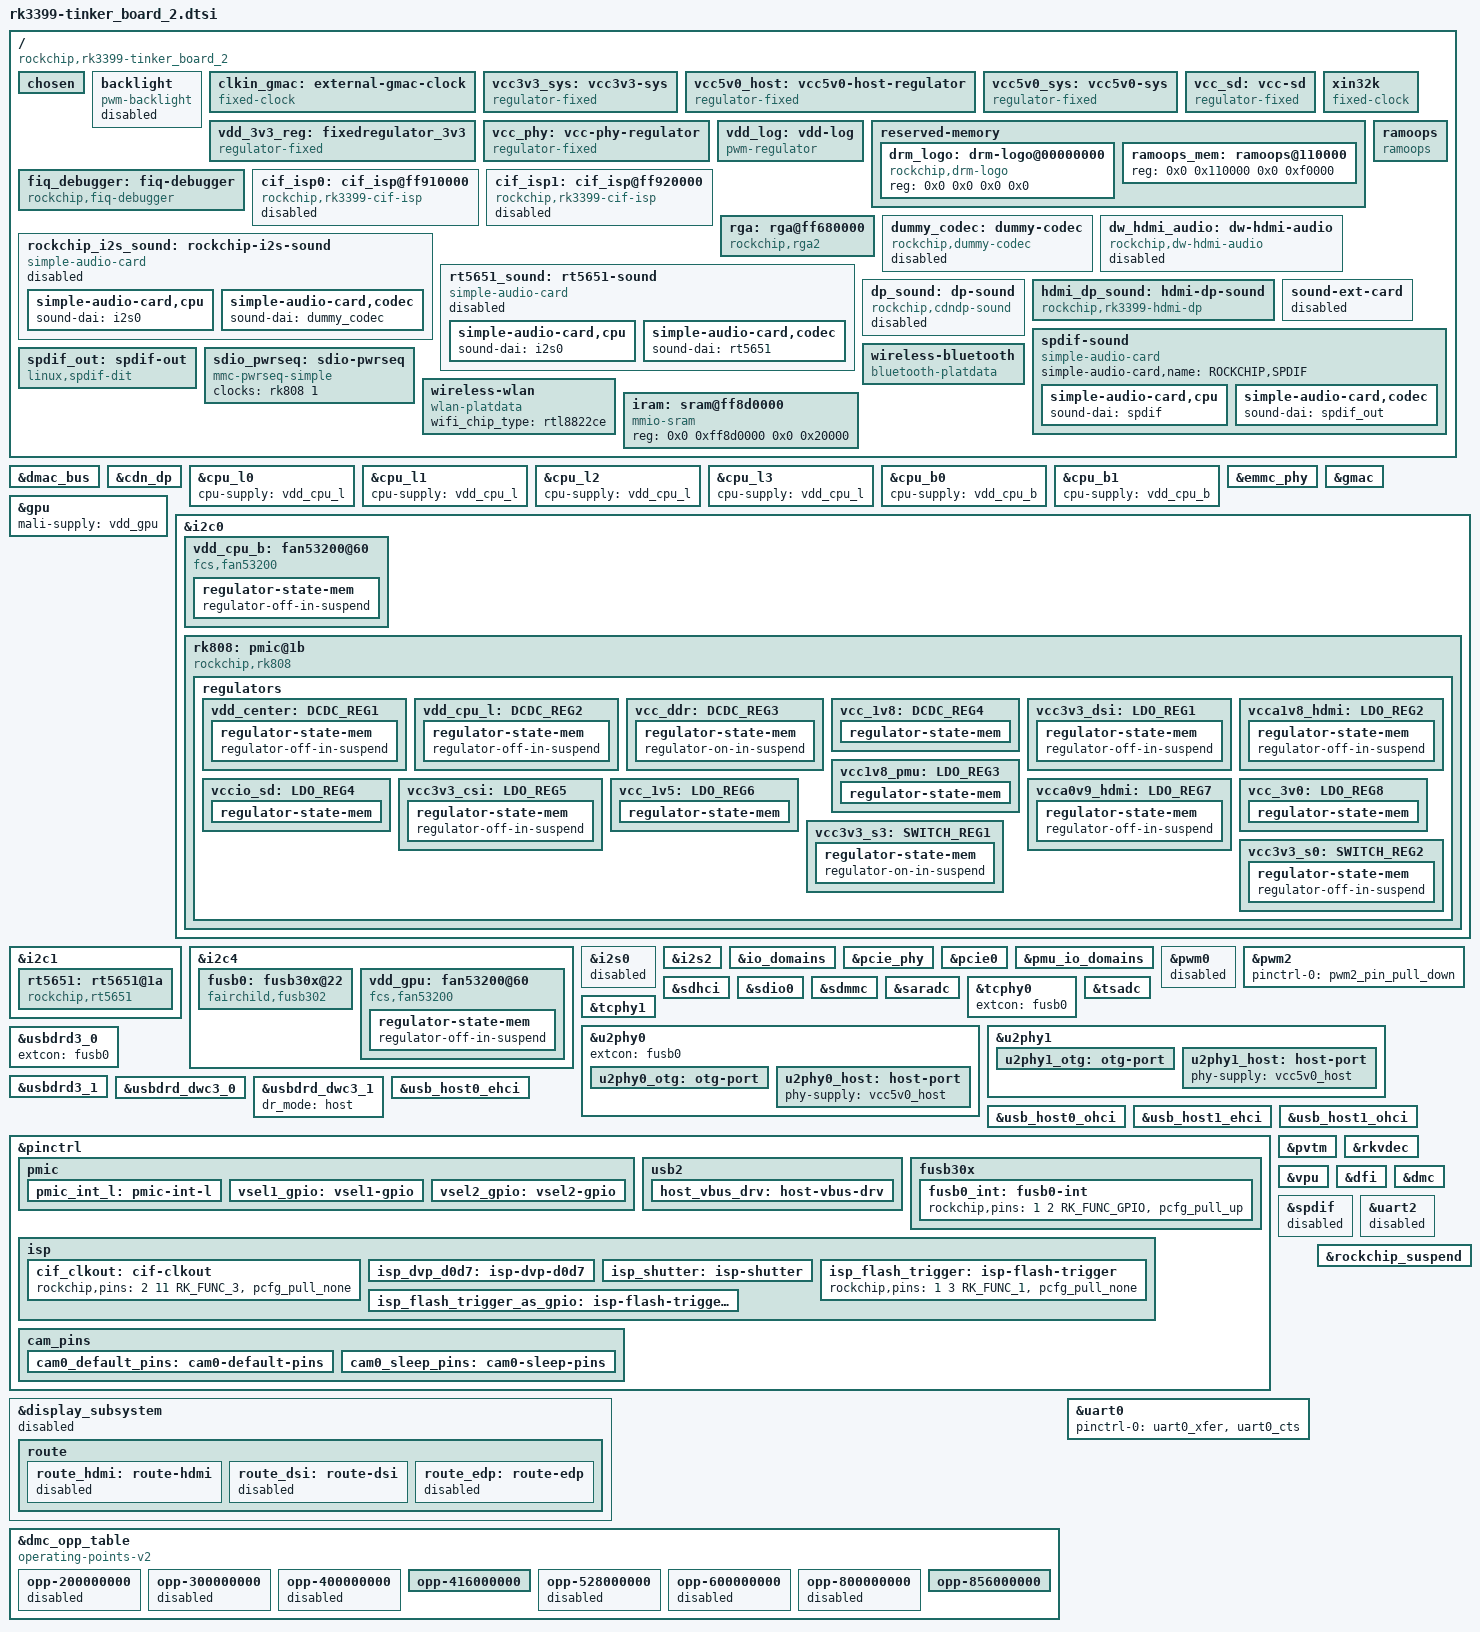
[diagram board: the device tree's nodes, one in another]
/*
 * Copyright (c) 2016 Fuzhou Rockchip Electronics Co., Ltd
 *
 * This file is dual-licensed: you can use it either under the terms
 * of the GPL or the X11 license, at your option. Note that this dual
 * licensing only applies to this file, and not this project as a
 * whole.
 *
 *  a) This file is free software; you can redistribute it and/or
 *     modify it under the terms of the GNU General Public License as
 *     published by the Free Software Foundation; either version 2 of the
 *     License, or (at your option) any later version.
 *
 *     This file is distributed in the hope that it will be useful,
 *     but WITHOUT ANY WARRANTY; without even the implied warranty of
 *     MERCHANTABILITY or FITNESS FOR A PARTICULAR PURPOSE.  See the
 *     GNU General Public License for more details.
 *
 * Or, alternatively,
 *
 *  b) Permission is hereby granted, free of charge, to any person
 *     obtaining a copy of this software and associated documentation
 *     files (the "Software"), to deal in the Software without
 *     restriction, including without limitation the rights to use,
 *     copy, modify, merge, publish, distribute, sublicense, and/or
 *     sell copies of the Software, and to permit persons to whom the
 *     Software is furnished to do so, subject to the following
 *     conditions:
 *
 *     The above copyright notice and this permission notice shall be
 *     included in all copies or substantial portions of the Software.
 *
 *     THE SOFTWARE IS PROVIDED "AS IS", WITHOUT WARRANTY OF ANY KIND,
 *     EXPRESS OR IMPLIED, INCLUDING BUT NOT LIMITED TO THE WARRANTIES
 *     OF MERCHANTABILITY, FITNESS FOR A PARTICULAR PURPOSE AND
 *     NONINFRINGEMENT. IN NO EVENT SHALL THE AUTHORS OR COPYRIGHT
 *     HOLDERS BE LIABLE FOR ANY CLAIM, DAMAGES OR OTHER LIABILITY,
 *     WHETHER IN AN ACTION OF CONTRACT, TORT OR OTHERWISE, ARISING
 *     FROM, OUT OF OR IN CONNECTION WITH THE SOFTWARE OR THE USE OR
 *     OTHER DEALINGS IN THE SOFTWARE.
 */

#include <dt-bindings/display/drm_mipi_dsi.h>
#include "dt-bindings/pwm/pwm.h"
#include <dt-bindings/soc/rockchip-io-domain.h>
#include "rk3399.dtsi"
#include "rk3399-opp.dtsi"
#include "rk3399-vop-clk-set.dtsi"

/ {
	compatible = "rockchip,rk3399-tinker_board_2", "rockchip,rk3399";

	chosen {
		bootargs = "earlycon=uart8250,mmio32,0xff1a0000 swiotlb=1 console=ttyFIQ0 rw rootfstype=ext4 rootwait coherent_pool=1m";
	};

	backlight: backlight {
		status = "disabled";
		compatible = "pwm-backlight";
		//pwms = <&pwm0 0 25000 0>;
		brightness-levels = <
			  0   1   2   3   4   5   6   7
			  8   9  10  11  12  13  14  15
			 16  17  18  19  20  21  22  23
			 24  25  26  27  28  29  30  31
			 32  33  34  35  36  37  38  39
			 40  41  42  43  44  45  46  47
			 48  49  50  51  52  53  54  55
			 56  57  58  59  60  61  62  63
			 64  65  66  67  68  69  70  71
			 72  73  74  75  76  77  78  79
			 80  81  82  83  84  85  86  87
			 88  89  90  91  92  93  94  95
			 96  97  98  99 100 101 102 103
			104 105 106 107 108 109 110 111
			112 113 114 115 116 117 118 119
			120 121 122 123 124 125 126 127
			128 129 130 131 132 133 134 135
			136 137 138 139 140 141 142 143
			144 145 146 147 148 149 150 151
			152 153 154 155 156 157 158 159
			160 161 162 163 164 165 166 167
			168 169 170 171 172 173 174 175
			176 177 178 179 180 181 182 183
			184 185 186 187 188 189 190 191
			192 193 194 195 196 197 198 199
			200 201 202 203 204 205 206 207
			208 209 210 211 212 213 214 215
			216 217 218 219 220 221 222 223
			224 225 226 227 228 229 230 231
			232 233 234 235 236 237 238 239
			240 241 242 243 244 245 246 247
			248 249 250 251 252 253 254 255>;
		default-brightness-level = <200>;
	};

	clkin_gmac: external-gmac-clock {
		compatible = "fixed-clock";
		clock-frequency = <125000000>;
		clock-output-names = "clkin_gmac";
		#clock-cells = <0>;
	};

	vcc3v3_sys: vcc3v3-sys {
		compatible = "regulator-fixed";
		regulator-name = "vcc3v3_sys";
		regulator-always-on;
		regulator-boot-on;
		regulator-min-microvolt = <3300000>;
		regulator-max-microvolt = <3300000>;
	};

	vcc5v0_host: vcc5v0-host-regulator {
		compatible = "regulator-fixed";
		enable-active-high;
		gpio = <&gpio4 25 GPIO_ACTIVE_HIGH>;
		pinctrl-names = "default";
		pinctrl-0 = <&host_vbus_drv>;
		regulator-name = "vcc5v0_host";
		regulator-always-on;
	};

	vcc5v0_sys: vcc5v0-sys {
		compatible = "regulator-fixed";
		regulator-name = "vcc5v0_sys";
		regulator-always-on;
		regulator-boot-on;
		regulator-min-microvolt = <5000000>;
		regulator-max-microvolt = <5000000>;
	};

	vcc_sd: vcc-sd {
		compatible = "regulator-fixed";
		enable-active-high;
		pinctrl-names = "default";
		regulator-name = "vcc_sd";
		regulator-min-microvolt = <3300000>;
		regulator-max-microvolt = <3300000>;
	};

	vdd_3v3_reg: fixedregulator_3v3 {
		compatible = "regulator-fixed";
		regulator-name = "3v3";
		regulator-min-microvolt = <3300000>;
		regulator-max-microvolt = <3300000>;
		regulator-always-on;
	};

	vcc_phy: vcc-phy-regulator {
		compatible = "regulator-fixed";
		regulator-name = "vcc_phy";
		regulator-always-on;
		regulator-boot-on;
	};

	vdd_log: vdd-log {
		compatible = "pwm-regulator";
		pwms = <&pwm2 0 25000 1>;
		regulator-name = "vdd_log";
		regulator-min-microvolt = <800000>;
		regulator-max-microvolt = <1400000>;
		regulator-always-on;
		regulator-boot-on;

		/* for rockchip boot on */
		rockchip,pwm_id= <2>;
		rockchip,pwm_voltage = <900000>;
	};

	xin32k: xin32k {
		compatible = "fixed-clock";
		clock-frequency = <32768>;
		clock-output-names = "xin32k";
		#clock-cells = <0>;
	};

	reserved-memory {
		#address-cells = <2>;
		#size-cells = <2>;
		ranges;

		drm_logo: drm-logo@00000000 {
			compatible = "rockchip,drm-logo";
			reg = <0x0 0x0 0x0 0x0>;
		};

		ramoops_mem: ramoops@110000 {
			reg = <0x0 0x110000 0x0 0xf0000>;
			reg-names = "ramoops_mem";
		};
	};

	ramoops: ramoops {
		compatible = "ramoops";
		record-size = <0x0 0x40000>;
		console-size = <0x0 0x80000>;
		ftrace-size = <0x0 0x00000>;
		pmsg-size = <0x0 0x00000>;
		memory-region = <&ramoops_mem>;
	};

	fiq_debugger: fiq-debugger {
		compatible = "rockchip,fiq-debugger";
		rockchip,serial-id = <2>;
		rockchip,signal-irq = <182>;
		rockchip,wake-irq = <0>;
		rockchip,irq-mode-enable = <1>;  /* If enable uart uses irq instead of fiq */
		rockchip,baudrate = <1500000>;  /* Only 115200 and 1500000 */
		pinctrl-names = "default";
		pinctrl-0 = <&uart2c_xfer>;
		status = "okay";
	};

	cif_isp0: cif_isp@ff910000 {
		compatible = "rockchip,rk3399-cif-isp";
		rockchip,grf = <&grf>;
		reg = <0x0 0xff910000 0x0 0x4000>, <0x0 0xff968000 0x0 0x8000>;
		reg-names = "register", "dsihost-register";
		clocks =
			<&cru ACLK_ISP0_NOC>, <&cru ACLK_ISP0_WRAPPER>,
			<&cru HCLK_ISP0_NOC>, <&cru HCLK_ISP0_WRAPPER>,
			<&cru SCLK_ISP0>, <&cru SCLK_DPHY_RX0_CFG>,
			<&cru SCLK_CIF_OUT>, <&cru SCLK_CIF_OUT>,
			<&cru SCLK_MIPIDPHY_REF>;
		clock-names =
			"aclk_isp0_noc", "aclk_isp0_wrapper",
			"hclk_isp0_noc", "hclk_isp0_wrapper",
			"clk_isp0", "pclk_dphyrx",
			"clk_cif_out", "clk_cif_pll",
			"pclk_dphy_ref";
		interrupts = <GIC_SPI 43 IRQ_TYPE_LEVEL_HIGH 0>;
		interrupt-names = "cif_isp10_irq";
		power-domains = <&power RK3399_PD_ISP0>;
		rockchip,isp,iommu-enable = <1>;
		iommus = <&isp0_mmu>;
		status = "disabled";
	};

	cif_isp1: cif_isp@ff920000 {
		compatible = "rockchip,rk3399-cif-isp";
		rockchip,grf = <&grf>;
		reg = <0x0 0xff920000 0x0 0x4000>, <0x0 0xff968000 0x0 0x8000>;
		reg-names = "register", "dsihost-register";
		clocks =
			<&cru ACLK_ISP1_NOC>, <&cru ACLK_ISP1_WRAPPER>,
			<&cru HCLK_ISP1_NOC>, <&cru HCLK_ISP1_WRAPPER>,
			<&cru SCLK_ISP1>, <&cru PCLK_ISP1_WRAPPER>,
			<&cru SCLK_DPHY_TX1RX1_CFG>,
			<&cru PCLK_MIPI_DSI1>, <&cru SCLK_MIPIDPHY_CFG>,
			<&cru SCLK_CIF_OUT>, <&cru SCLK_CIF_OUT>,
			<&cru SCLK_MIPIDPHY_REF>;
		clock-names =
			"aclk_isp1_noc", "aclk_isp1_wrapper",
			"hclk_isp1_noc", "hclk_isp1_wrapper",
			"clk_isp1", "pclkin_isp1",
			"pclk_dphytxrx",
			"pclk_mipi_dsi","mipi_dphy_cfg",
			"clk_cif_out", "clk_cif_pll",
			"pclk_dphy_ref";
		interrupts = <GIC_SPI 44 IRQ_TYPE_LEVEL_HIGH 0>;
		interrupt-names = "cif_isp10_irq";
		power-domains = <&power RK3399_PD_ISP1>;
		rockchip,isp,iommu-enable = <1>;
		iommus = <&isp1_mmu>;
		status = "disabled";
	};

	rga: rga@ff680000 {
		compatible = "rockchip,rga2";
		dev_mode = <1>;
		reg = <0x0 0xff680000 0x0 0x1000>;
		interrupts = <GIC_SPI 55 IRQ_TYPE_LEVEL_HIGH 0>;
		clocks = <&cru ACLK_RGA>, <&cru HCLK_RGA>, <&cru SCLK_RGA_CORE>;
		clock-names = "aclk_rga", "hclk_rga", "clk_rga";
		power-domains = <&power RK3399_PD_RGA>;
		status = "okay";
	};

	dummy_codec: dummy-codec {
		status = "disabled";
		compatible = "rockchip,dummy-codec";
		#sound-dai-cells = <0>;
		clocks = <&cru SCLK_I2S_8CH_OUT>;
		clock-names = "mclk";
		pinctrl-names = "default";
		pinctrl-0 = <&i2s_8ch_mclk>;
	};

	rockchip_i2s_sound: rockchip-i2s-sound {
		status = "disabled";
		compatible = "simple-audio-card";
		simple-audio-card,name = "rockchip,rockchip-i2s-sound";
		simple-audio-card,format = "i2s";
		simple-audio-card,mclk-fs = <256>;
		simple-audio-card,cpu {
			sound-dai = <&i2s0>;
		};
		simple-audio-card,codec {
			sound-dai = <&dummy_codec>;
		};
	};

	rt5651_sound: rt5651-sound {
		status = "disabled";
		compatible = "simple-audio-card";
		simple-audio-card,format = "i2s";
		simple-audio-card,name = "realtek,rt5651-codec";
		simple-audio-card,mclk-fs = <256>;
		simple-audio-card,widgets =
			"Microphone", "Mic Jack",
			"Headphone", "Headphone Jack";
		simple-audio-card,routing =
			"Mic Jack", "MICBIAS1",
			"IN1P", "Mic Jack",
			"Headphone Jack", "HPOL",
			"Headphone Jack", "HPOR";
		simple-audio-card,cpu {
			sound-dai = <&i2s0>;
		};
		simple-audio-card,codec {
			sound-dai = <&rt5651>;
		};
	};

	dw_hdmi_audio: dw-hdmi-audio {
		status = "disabled";
		compatible = "rockchip,dw-hdmi-audio";
		#sound-dai-cells = <0>;
	};

	dp_sound: dp-sound {
		status = "disabled";
		compatible = "rockchip,cdndp-sound";
		rockchip,cpu = <&spdif>;
		rockchip,codec = <&cdn_dp 1>;
	};

/*
	hdmi_sound: hdmi-sound {
		status = "okay";
		compatible = "simple-audio-card";
		simple-audio-card,format = "i2s";
		simple-audio-card,mclk-fs = <256>;
		simple-audio-card,name = "rockchip,hdmi";

		simple-audio-card,cpu {
			sound-dai = <&i2s2>;
		};
		simple-audio-card,codec {
			sound-dai = <&hdmi>;
		};
	};
*/

	hdmi_dp_sound: hdmi-dp-sound {
		status = "okay";
		compatible = "rockchip,rk3399-hdmi-dp";
		rockchip,cpu = <&i2s2>;
		rockchip,codec = <&hdmi>, <&cdn_dp>;
	};

	sound-ext-card {
		status = "disabled";
	};

	spdif-sound {
		status = "okay";
		compatible = "simple-audio-card";
		simple-audio-card,name = "ROCKCHIP,SPDIF";
		simple-audio-card,cpu {
			sound-dai = <&spdif>;
		};
		simple-audio-card,codec {
			sound-dai = <&spdif_out>;
		};
	};

	spdif_out: spdif-out {
		status = "okay";
		compatible = "linux,spdif-dit";
		#sound-dai-cells = <0>;
	};

	sdio_pwrseq: sdio-pwrseq {
		compatible = "mmc-pwrseq-simple";
		clocks = <&rk808 1>;
		clock-names = "ext_clock";
		pinctrl-names = "default";
		//pinctrl-0 = <&wifi_enable_h>;

		/*
		 * On the module itself this is one of these (depending
		 * on the actual card populated):
		 * - SDIO_RESET_L_WL_REG_ON
		 * - PDN (power down when low)
		 */
		//reset-gpios = <&gpio0 10 GPIO_ACTIVE_LOW>; /* GPIO0_B2 */
	};

	wireless-wlan {
		compatible = "wlan-platdata";
		wifi_chip_type = "rtl8822ce";
		status = "okay";
	};

	wireless-bluetooth {
		compatible = "bluetooth-platdata";
		clocks = <&rk808 1>;
		clock-names = "ext_clock";
		//wifi-bt-power-toggle;
		//uart_rts_gpios = <&gpio2 19 GPIO_ACTIVE_LOW>; /* GPIO2_C3 */
		//pinctrl-names = "default", "rts_gpio";
		//pinctrl-0 = <&uart0_rts>;
		//pinctrl-1 = <&uart0_gpios>;
		//BT,power_gpio  = <&gpio3 19 GPIO_ACTIVE_HIGH>; /* GPIOx_xx */
		//BT,reset_gpio    = <&gpio0 9 GPIO_ACTIVE_HIGH>; /* GPIO0_B1 */
		BT,wake_gpio     = <&gpio2 26 GPIO_ACTIVE_HIGH>; /* GPIO2_D2 */
		//BT,wake_host_irq = <&gpio0 4 GPIO_ACTIVE_HIGH>; /* GPIO0_A4 */
		status = "okay";
	};

	/* first 64k(0xff8c0000~0xff8d0000) for ddr and suspend */
	iram: sram@ff8d0000 {
		compatible = "mmio-sram";
		reg = <0x0 0xff8d0000 0x0 0x20000>; /* 128k */
	};
};

&dmac_bus {
	iram = <&iram>;
	rockchip,force-iram;
};

&cdn_dp {
	status = "okay";
	extcon = <&fusb0>;
	phys = <&tcphy0_dp>;
};

&cpu_l0 {
	cpu-supply = <&vdd_cpu_l>;
};

&cpu_l1 {
	cpu-supply = <&vdd_cpu_l>;
};

&cpu_l2 {
	cpu-supply = <&vdd_cpu_l>;
};

&cpu_l3 {
	cpu-supply = <&vdd_cpu_l>;
};

&cpu_b0 {
	cpu-supply = <&vdd_cpu_b>;
};

&cpu_b1 {
	cpu-supply = <&vdd_cpu_b>;
};

&emmc_phy {
	status = "okay";
};

&gmac {
	phy-supply = <&vcc_phy>;
	phy-mode = "rgmii";
	clock_in_out = "output";
	snps,reset-gpio = <&gpio3 15 GPIO_ACTIVE_LOW>;
	snps,reset-active-low;
	snps,reset-delays-us = <0 16000 72000>;
	assigned-clocks = <&cru SCLK_RMII_SRC>;
	assigned-clock-parents = <&cru SCLK_MAC>;
	assigned-clock-rates = <125000000>;
	wolirq-gpio = <&gpio3 16 GPIO_ACTIVE_LOW>;
	pinctrl-names = "default";
	pinctrl-0 = <&rgmii_pins>;
	tx_delay = <0x25>;
	rx_delay = <0x20>;
	wakeup-enable = "0";
	status = "okay";
};

&gpu {
	status = "okay";
	mali-supply = <&vdd_gpu>;
};

&i2c0 {
	status = "okay";
	i2c-scl-rising-time-ns = <168>;
	i2c-scl-falling-time-ns = <4>;
	clock-frequency = <400000>;

	vdd_cpu_b: fan53200@60 {
		compatible = "fcs,fan53200";
		reg = <0x60>;
		vin-supply = <&vcc5v0_sys>;
		regulator-compatible = "fan53555-reg";
		pinctrl-names = "default";
		pinctrl-0 = <&vsel1_gpio>;
		vsel-gpios = <&gpio1 17 GPIO_ACTIVE_HIGH>;
		regulator-name = "vdd_cpu_b";
		regulator-min-microvolt = <800000>;
		regulator-max-microvolt = <1250000>;
		regulator-ramp-delay = <1000>;
		fcs,suspend-voltage-selector = <0>;
		regulator-always-on;
		regulator-boot-on;
		regulator-initial-state = <3>;
			regulator-state-mem {
			regulator-off-in-suspend;
		};
	};

	rk808: pmic@1b {
		compatible = "rockchip,rk808";
		reg = <0x1b>;
		interrupt-parent = <&gpio1>;
		interrupts = <18 IRQ_TYPE_LEVEL_LOW>;
		pinctrl-names = "default";
		pinctrl-0 = <&pmic_int_l>;
		rockchip,system-power-controller;
		wakeup-source;
		#clock-cells = <1>;
		clock-output-names = "rk808-clkout1", "rk808-clkout2";

		vcc1-supply = <&vcc3v3_sys>;
		vcc2-supply = <&vcc3v3_sys>;
		vcc3-supply = <&vcc3v3_sys>;
		vcc4-supply = <&vcc3v3_sys>;
		vcc6-supply = <&vcc3v3_sys>;
		vcc7-supply = <&vcc3v3_sys>;
		vcc8-supply = <&vcc3v3_sys>;
		vcc9-supply = <&vcc3v3_sys>;
		vcc10-supply = <&vcc3v3_sys>;
		vcc11-supply = <&vcc3v3_sys>;
		vcc12-supply = <&vcc3v3_sys>;
		vddio-supply = <&vcc_3v0>;

		regulators {
			vdd_center: DCDC_REG1 {
				regulator-always-on;
				regulator-boot-on;
				regulator-min-microvolt = <750000>;
				regulator-max-microvolt = <1350000>;
				regulator-ramp-delay = <6001>;
				regulator-name = "vdd_center";
				regulator-state-mem {
					regulator-off-in-suspend;
				};
			};

			vdd_cpu_l: DCDC_REG2 {
				regulator-always-on;
				regulator-boot-on;
				regulator-min-microvolt = <750000>;
				regulator-max-microvolt = <1350000>;
				regulator-ramp-delay = <6001>;
				regulator-name = "vdd_cpu_l";
				regulator-state-mem {
					regulator-off-in-suspend;
				};
			};

			vcc_ddr: DCDC_REG3 {
				regulator-always-on;
				regulator-boot-on;
				regulator-name = "vcc_ddr";
				regulator-state-mem {
					regulator-on-in-suspend;
				};
			};

			vcc_1v8: DCDC_REG4 {
				regulator-always-on;
				regulator-boot-on;
				regulator-min-microvolt = <1800000>;
				regulator-max-microvolt = <1800000>;
				regulator-name = "vcc_1v8";
				regulator-state-mem {
					regulator-on-in-suspend;
					regulator-suspend-microvolt = <1800000>;
				};
			};

			vcc3v3_dsi: LDO_REG1 {
				regulator-always-on;
				regulator-boot-on;
				regulator-min-microvolt = <3300000>;
				regulator-max-microvolt = <3300000>;
				regulator-name = "vcc3v3_dsi";
				regulator-state-mem {
					regulator-off-in-suspend;
				};
			};

			vcca1v8_hdmi: LDO_REG2 {
				regulator-always-on;
				regulator-boot-on;
				regulator-min-microvolt = <1800000>;
				regulator-max-microvolt = <1800000>;
				regulator-name = "vcca1v8_hdmi";
				regulator-state-mem {
					regulator-off-in-suspend;
				};
			};

			vcc1v8_pmu: LDO_REG3 {
				regulator-always-on;
				regulator-boot-on;
				regulator-min-microvolt = <1800000>;
				regulator-max-microvolt = <1800000>;
				regulator-name = "vcc1v8_pmu";
				regulator-state-mem {
					regulator-on-in-suspend;
					regulator-suspend-microvolt = <1800000>;
				};
			};

			vccio_sd: LDO_REG4 {
				regulator-always-on;
				regulator-boot-on;
				regulator-min-microvolt = <1800000>;
				regulator-max-microvolt = <3000000>;
				regulator-name = "vccio_sd";
				regulator-state-mem {
					regulator-on-in-suspend;
					regulator-suspend-microvolt = <3000000>;
				};
			};

			vcc3v3_csi: LDO_REG5 {
				regulator-always-on;
				regulator-boot-on;
				regulator-min-microvolt = <3300000>;
				regulator-max-microvolt = <3300000>;
				regulator-name = "vcc3v3_csi";
				regulator-state-mem {
					regulator-off-in-suspend;
				};
			};

			vcc_1v5: LDO_REG6 {
				regulator-always-on;
				regulator-boot-on;
				regulator-min-microvolt = <1500000>;
				regulator-max-microvolt = <1500000>;
				regulator-name = "vcc_1v5";
				regulator-state-mem {
					regulator-on-in-suspend;
					regulator-suspend-microvolt = <1500000>;
				};
			};

			vcca0v9_hdmi: LDO_REG7 {
				regulator-always-on;
				regulator-boot-on;
				regulator-min-microvolt = <900000>;
				regulator-max-microvolt = <900000>;
				regulator-name = "vcca0v9_hdmi";
				regulator-state-mem {
					regulator-off-in-suspend;
				};
			};

			vcc_3v0: LDO_REG8 {
				regulator-always-on;
				regulator-boot-on;
				regulator-min-microvolt = <3000000>;
				regulator-max-microvolt = <3000000>;
				regulator-name = "vcc_3v0";
				regulator-state-mem {
					regulator-on-in-suspend;
					regulator-suspend-microvolt = <3000000>;
				};
			};

			vcc3v3_s3: SWITCH_REG1 {
				regulator-always-on;
				regulator-boot-on;
				regulator-name = "vcc3v3_s3";
				regulator-state-mem {
					regulator-on-in-suspend;
				};
			};

			vcc3v3_s0: SWITCH_REG2 {
				regulator-always-on;
				regulator-boot-on;
				regulator-name = "vcc3v3_s0";
				regulator-state-mem {
					regulator-off-in-suspend;
				};
			};
		};
	};
};

&i2c1 {
	status = "okay";
	i2c-scl-rising-time-ns = <300>;
	i2c-scl-falling-time-ns = <15>;

	rt5651: rt5651@1a {
		#sound-dai-cells = <0>;
		compatible = "rockchip,rt5651";
		reg = <0x1a>;
		clocks = <&cru SCLK_I2S_8CH_OUT>;
		clock-names = "mclk";
		pinctrl-names = "default";
		pinctrl-0 = <&i2s_8ch_mclk>;
		spk-con-gpio = <&gpio0 11 GPIO_ACTIVE_HIGH>;
		hp-det-gpio = <&gpio4 28 GPIO_ACTIVE_LOW>;
	};
};

&i2c4 {
	status = "okay";
	i2c-scl-rising-time-ns = <475>;
	i2c-scl-falling-time-ns = <26>;

	fusb0: fusb30x@22 {
		compatible = "fairchild,fusb302";
		reg = <0x22>;
		pinctrl-names = "default";
		pinctrl-0 = <&fusb0_int>;
		int-n-gpios = <&gpio1 2 GPIO_ACTIVE_HIGH>;
		//vbus-5v-gpios = <&gpio2 0 GPIO_ACTIVE_HIGH>;
		status = "okay";
	};

	vdd_gpu: fan53200@60 {
		compatible = "fcs,fan53200";
		reg = <0x60>;
		vin-supply = <&vcc5v0_sys>;
		regulator-compatible = "fan53555-reg";
		pinctrl-names = "default";
		pinctrl-0 = <&vsel2_gpio>;
		vsel-gpios = <&gpio1 14 GPIO_ACTIVE_HIGH>;
		regulator-name = "vdd_gpu";
		regulator-min-microvolt = <800000>;
		regulator-max-microvolt = <1200000>;
		regulator-ramp-delay = <1000>;
		fcs,suspend-voltage-selector = <0>;
		regulator-always-on;
		regulator-boot-on;
		regulator-initial-state = <3>;
			regulator-state-mem {
			regulator-off-in-suspend;
		};
	};
};

&i2s0 {
	status = "disable";
	rockchip,i2s-broken-burst-len;
	rockchip,playback-channels = <8>;
	rockchip,capture-channels = <8>;
	#sound-dai-cells = <0>;
};

&i2s2 {
	#sound-dai-cells = <0>;
	status = "okay";
};

&io_domains {
	status = "okay";

	/*
	 * If the uboot use rkdevelop branch, the io-domain is not set
	 * during uboot phase, it will cause the io voltage is not suit for
	 * the hardware,maybe will damage the io of rk3399, so we add
	 * uboot-set value to make sure the value is same with the kernel,
	 * ofcause you must make sure firstly the value here is suit for your
	 * hardware. The available value is defined in
	 * include/dt-bindings/soc/rockchip-io-domain.h, they are
	 * also list here for more convenient configuration:
	 * bt656-supply: RK3399_BT656_VDD_1V8 or RK3399_BT656_VDD_3V3
	 * audio-supply: RK3399_AUDIO_VDD_1V8 or RK3399_AUDIO_VDD_3V3
	 * gpio1830-supply: RK3399_GPIO1833_VDD_1V8 or RK3399_GPIO1833_VDD_3V3
	 * sdmmc-supply: don't need to configure because the voltage
	 *                       is set in source code during runtime.
	 * NOTE:
	 * 1. The value in uboot-set must be enclosed in "()", otherwise will
	 *     cause compile error.
	 * 2. The uboot-set configuration must be cooperated with submit
	 *     in u-boot.
	 */
	uboot-set = <(RK3399_BT656_VDD_3V3 | RK3399_AUDIO_VDD_1V8 |
				RK3399_GPIO1833_VDD_3V3)>;
	bt656-supply = <&vcc_3v0>;		/* bt656_gpio2ab_ms */
	audio-supply = <&vcc_3v0>;		/* audio_gpio3d4a_ms */
	sdmmc-supply = <&vccio_sd>;		/* sdmmc_gpio4b_ms */
	gpio1830-supply = <&vcc_3v0>;		/* gpio1833_gpio4cd_ms */
};

&pcie_phy {
	status = "okay";
};

&pcie0 {
	ep-gpios = <&gpio0 12 GPIO_ACTIVE_HIGH>;
	num-lanes = <4>;
	pinctrl-names = "default";
	pinctrl-0 = <&pcie_clkreqn>;
	status = "okay";
};

&pmu_io_domains {
	status = "okay";
	/*
	 * If the uboot use rkdevelop branch, the pmu_io_domain is not set
	 * during uboot phase, it will cause the io voltage is not suit for
	 * the hardware,maybe will damage the io of rk3399, so we add
	 * uboot-set value to make sure the value is same with the kernel,
	 * ofcause you must make sure firstly the value here is suit for your
	 * hardware. The available value is defined in
	 * include/dt-bindings/soc/rockchip-io-domain.h, they are
	 * also list here for more convenient configuration:
	 * pmu1830-supply: RK3399_PMU1830_VDD_1V8 or RK3399_PMU1830_VDD_3V0
	 */
	uboot-set = <RK3399_PMU1830_VDD_3V0>;
	pmu1830-supply = <&vcc_3v0>;
};

&pwm0 {
	status = "disable";
};

&pwm2 {
	status = "okay";
	pinctrl-names = "active";
	pinctrl-0 = <&pwm2_pin_pull_down>;
};

&sdhci {
	bus-width = <8>;
	mmc-hs400-1_8v;
	supports-emmc;
	non-removable;
	keep-power-in-suspend;
	mmc-hs400-enhanced-strobe;
	status = "okay";
};

&sdio0 {
	clock-frequency = <50000000>;
	clock-freq-min-max = <200000 50000000>;
	supports-sdio;
	bus-width = <4>;
	disable-wp;
	cap-sd-highspeed;
	cap-sdio-irq;
	keep-power-in-suspend;
	mmc-pwrseq = <&sdio_pwrseq>;
	non-removable;
	num-slots = <1>;
	pinctrl-names = "default";
	sd-uhs-sdr104;
	status = "okay";
};

&sdmmc {
	clock-frequency = <150000000>;
	clock-freq-min-max = <100000 150000000>;
	supports-sd;
	bus-width = <4>;
	cap-mmc-highspeed;
	cap-sd-highspeed;
	disable-wp;
	num-slots = <1>;
	//sd-uhs-sdr104;
	vmmc-supply = <&vcc_sd>;
	vqmmc-supply = <&vccio_sd>;
	pinctrl-names = "default";
	pinctrl-0 = <&sdmmc_clk &sdmmc_cmd &sdmmc_cd &sdmmc_bus4>;
	status = "okay";
};

&saradc {
	status = "okay";
};

&tcphy0 {
	extcon = <&fusb0>;
	status = "okay";
};

&tcphy1 {
	status = "okay";
};

&tsadc {
	/* tshut mode 0:CRU 1:GPIO */
	rockchip,hw-tshut-mode = <1>;
	/* tshut polarity 0:LOW 1:HIGH */
	rockchip,hw-tshut-polarity = <1>;
	status = "okay";
};

&u2phy0 {
	status = "okay";
	extcon = <&fusb0>;

	u2phy0_otg: otg-port {
		status = "okay";
	};

	u2phy0_host: host-port {
		phy-supply = <&vcc5v0_host>;
		status = "okay";
	};
};

&u2phy1 {
	status = "okay";

	u2phy1_otg: otg-port {
		status = "okay";
	};

	u2phy1_host: host-port {
		phy-supply = <&vcc5v0_host>;
		status = "okay";
	};
};

&usbdrd3_0 {
	status = "okay";
	extcon = <&fusb0>;
};

&usbdrd3_1 {
	status = "okay";
};

&usbdrd_dwc3_0 {
	status = "okay";
};

&usbdrd_dwc3_1 {
	status = "okay";
	dr_mode = "host";
};

&usb_host0_ehci {
	status = "okay";
};

&usb_host0_ohci {
	status = "okay";
};

&usb_host1_ehci {
	status = "okay";
};

&usb_host1_ohci {
	status = "okay";
};

&pinctrl {
	pmic {
		pmic_int_l: pmic-int-l {
			rockchip,pins =
				<1 18 RK_FUNC_GPIO &pcfg_pull_up>,
				<0 9 RK_FUNC_GPIO &pcfg_pull_none>; /* GPIO0_B1 */
		};
		vsel1_gpio: vsel1-gpio {
			rockchip,pins =
				<1 17 RK_FUNC_GPIO &pcfg_pull_down>;
		};
		vsel2_gpio: vsel2-gpio {
			rockchip,pins =
				<1 14 RK_FUNC_GPIO &pcfg_pull_down>;
		};
	};

	usb2 {
		host_vbus_drv: host-vbus-drv {
			rockchip,pins =
				<4 25 RK_FUNC_GPIO &pcfg_pull_none>;
		};
	};

	fusb30x {
		fusb0_int: fusb0-int {
			rockchip,pins = <1 2 RK_FUNC_GPIO &pcfg_pull_up>;
		};
	};

	isp {
		cif_clkout: cif-clkout {
			rockchip,pins =
				/* cif_clkout */
				<2 11 RK_FUNC_3 &pcfg_pull_none>;
		};

		isp_dvp_d0d7: isp-dvp-d0d7 {
			rockchip,pins =
				<4 27 RK_FUNC_GPIO &pcfg_pull_none>,
				/* cif_clkout */
				<2 11 RK_FUNC_3 &pcfg_pull_none>,
				/* cif_data0 */
				<2 2 RK_FUNC_3 &pcfg_pull_none>,
				/* cif_data3 */
				<2 3 RK_FUNC_3 &pcfg_pull_none>,
				/* cif_data4 */
				<2 4 RK_FUNC_3 &pcfg_pull_none>,
				/* cif_data5 */
				<2 5 RK_FUNC_3 &pcfg_pull_none>,
				/* cif_data6 */
				<2 6 RK_FUNC_3 &pcfg_pull_none>,
				/* cif_data7 */
				<2 7 RK_FUNC_3 &pcfg_pull_none>,
				/* cif_sync */
				<2 8 RK_FUNC_3 &pcfg_pull_none>,
				/* cif_href */
				<2 9 RK_FUNC_3 &pcfg_pull_none>,
				/* cif_clkin */
				<2 10 RK_FUNC_3 &pcfg_pull_none>;
		};

		isp_shutter: isp-shutter {
			rockchip,pins =
				/* SHUTTEREN */
				<1 1 RK_FUNC_1 &pcfg_pull_none>,
				/* SHUTTERTRIG */
				<1 0 RK_FUNC_1 &pcfg_pull_none>;
		};

		isp_flash_trigger: isp-flash-trigger {
			/* ISP_FLASHTRIGOU */
			rockchip,pins = <1 3 RK_FUNC_1 &pcfg_pull_none>;
		};

		isp_flash_trigger_as_gpio: isp-flash-trigger-as-gpio {
			/* ISP_FLASHTRIGOU */
			rockchip,pins = <0 17 RK_FUNC_GPIO &pcfg_pull_none>;
		};
	};

	cam_pins {
		cam0_default_pins: cam0-default-pins {
			rockchip,pins =
				<4 27 RK_FUNC_GPIO &pcfg_pull_none>,
				<2 11 RK_FUNC_3 &pcfg_pull_none>;
		};
		cam0_sleep_pins: cam0-sleep-pins {
			rockchip,pins =
				<4 27 RK_FUNC_3 &pcfg_pull_none>,
				<2 11 RK_FUNC_GPIO &pcfg_pull_none>;
		};
	};
};

&display_subsystem {
	status = "disabled";

	ports = <&vopb_out>, <&vopl_out>;
	logo-memory-region = <&drm_logo>;

	route {
		route_hdmi: route-hdmi {
			status = "disabled";
			logo,uboot = "logo.bmp";
			logo,kernel = "logo_kernel.bmp";
			logo,mode = "center";
			charge_logo,mode = "center";
			connect = <&vopb_out_hdmi>;
		};

		route_dsi: route-dsi {
			status = "disabled";
			logo,uboot = "logo.bmp";
			logo,kernel = "logo_kernel.bmp";
			logo,mode = "center";
			charge_logo,mode = "center";
			connect = <&vopl_out_dsi>;
		};

		route_edp: route-edp {
			status = "disabled";
			logo,uboot = "logo.bmp";
			logo,kernel = "logo_kernel.bmp";
			logo,mode = "center";
			charge_logo,mode = "center";
			connect = <&vopl_out_edp>;
		};
	};
};

&pvtm {
	status = "okay";
};

&rkvdec {
	status = "okay";
	/* 0 means ion, 1 means drm */
	//allocator = <0>;
};

&vpu {
	status = "okay";
	/* 0 means ion, 1 means drm */
	//allocator = <0>;
};

&dfi {
	status = "okay";
};

&dmc {
	status = "okay";
	center-supply = <&vdd_center>;
	upthreshold = <40>;
	downdifferential = <20>;
	system-status-freq = <
		/*system status         freq(KHz)*/
		SYS_STATUS_NORMAL       856000
		SYS_STATUS_REBOOT       416000
		SYS_STATUS_SUSPEND      416000
		SYS_STATUS_VIDEO_1080P  856000
		SYS_STATUS_VIDEO_4K     856000
		SYS_STATUS_VIDEO_4K_10B 856000
		SYS_STATUS_PERFORMANCE  856000
		SYS_STATUS_BOOST        856000
		SYS_STATUS_DUALVIEW     856000
		SYS_STATUS_ISP          856000
	>;
	vop-bw-dmc-freq = <
	/* min_bw(MB/s) max_bw(MB/s) freq(KHz) */
		0       577      416000
		578     99999    856000
	>;
	vop-pn-msch-readlatency = <
		0       0
		4       0x20
	>;
	auto-min-freq = <416000>;
	auto-freq-en = <1>;
};

&dmc_opp_table {
	compatible = "operating-points-v2";

	opp-200000000 {
		opp-hz = /bits/ 64 <200000000>;
		opp-microvolt = <900000>;
		status = "disabled";
	};
	opp-300000000 {
		opp-hz = /bits/ 64 <300000000>;
		opp-microvolt = <900000>;
		status = "disabled";
	};
	opp-400000000 {
		opp-hz = /bits/ 64 <400000000>;
		opp-microvolt = <900000>;
		status = "disabled";
	};
	opp-416000000 {
		opp-hz = /bits/ 64 <416000000>;
		opp-microvolt = <900000>;
	};
	opp-528000000 {
		opp-hz = /bits/ 64 <528000000>;
		opp-microvolt = <900000>;
		status = "disabled";
	};
	opp-600000000 {
		opp-hz = /bits/ 64 <600000000>;
		opp-microvolt = <900000>;
		status = "disabled";
	};
	opp-800000000 {
		opp-hz = /bits/ 64 <800000000>;
		opp-microvolt = <900000>;
		status = "disabled";
	};
	opp-856000000 {
		opp-hz = /bits/ 64 <856000000>;
		opp-microvolt = <900000>;
	};
};

&spdif {
	status = "disabled";
	pinctrl-0 = <&spdif_bus>;
	i2c-scl-rising-time-ns = <450>;
	i2c-scl-falling-time-ns = <15>;
	#sound-dai-cells = <0>;
};

&uart0 {
	pinctrl-names = "default";
	pinctrl-0 = <&uart0_xfer &uart0_cts>;
	status = "okay";
};

&uart2 {
	status = "disabled";
};

&rockchip_suspend {
	status = "okay";
	rockchip,sleep-debug-en = <1>;
	rockchip,sleep-mode-config = <
		(0
		| RKPM_SLP_ARMPD
		| RKPM_SLP_PERILPPD
		| RKPM_SLP_DDR_RET
		| RKPM_SLP_PLLPD
		| RKPM_SLP_CENTER_PD
		| RKPM_SLP_AP_PWROFF
		)
		>;
	rockchip,wakeup-config = <
		(0
		| RKPM_GPIO_WKUP_EN
		| RKPM_PWM_WKUP_EN
		)
		>;
		rockchip,pwm-regulator-config = <
		(0
		| PWM2_REGULATOR_EN
		)
		>;
		rockchip,power-ctrl =
		<&gpio1 17 GPIO_ACTIVE_HIGH>,
		<&gpio1 14 GPIO_ACTIVE_HIGH>;
};

